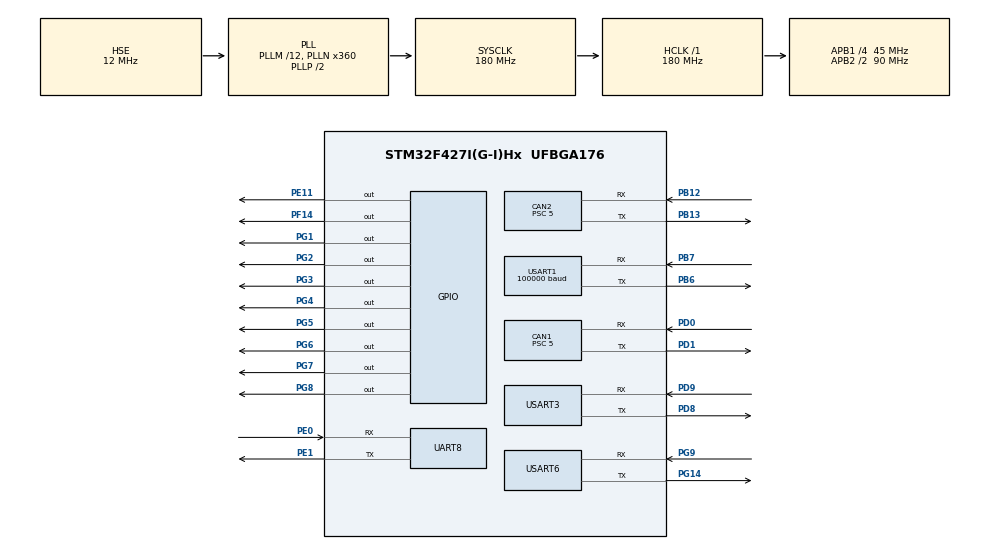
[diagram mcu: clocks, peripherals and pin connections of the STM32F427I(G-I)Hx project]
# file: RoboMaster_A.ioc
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CAN1.BS1=CAN_BS1_5TQ
CAN1.BS2=CAN_BS2_3TQ
CAN1.CalculateTimeQuantum=111.11111111111111
CAN1.Prescaler=5
CAN2.BS1=CAN_BS1_5TQ
CAN2.BS2=CAN_BS2_3TQ
CAN2.CalculateTimeQuantum=111.11111111111111
CAN2.Prescaler=5
Dma.Request0=USART1_RX
Dma.Request1=USART3_RX
Dma.Request2=USART6_RX
Dma.Request3=UART8_RX
Dma.UART8_RX.3.Direction=DMA_PERIPH_TO_MEMORY
Dma.UART8_RX.3.FIFOMode=DMA_FIFOMODE_DISABLE
Dma.UART8_RX.3.Instance=DMA1_Stream6
Dma.UART8_RX.3.MemDataAlignment=DMA_MDATAALIGN_BYTE
Dma.UART8_RX.3.MemInc=DMA_MINC_ENABLE
Dma.UART8_RX.3.Mode=DMA_CIRCULAR
Dma.UART8_RX.3.PeriphDataAlignment=DMA_PDATAALIGN_BYTE
Dma.UART8_RX.3.PeriphInc=DMA_PINC_DISABLE
Dma.UART8_RX.3.Priority=DMA_PRIORITY_LOW
Dma.USART1_RX.0.Direction=DMA_PERIPH_TO_MEMORY
Dma.USART1_RX.0.FIFOMode=DMA_FIFOMODE_DISABLE
Dma.USART1_RX.0.Instance=DMA2_Stream2
Dma.USART1_RX.0.MemDataAlignment=DMA_MDATAALIGN_BYTE
Dma.USART1_RX.0.MemInc=DMA_MINC_ENABLE
Dma.USART1_RX.0.Mode=DMA_CIRCULAR
Dma.USART1_RX.0.PeriphDataAlignment=DMA_PDATAALIGN_BYTE
Dma.USART1_RX.0.PeriphInc=DMA_PINC_DISABLE
Dma.USART1_RX.0.Priority=DMA_PRIORITY_LOW
Dma.USART3_RX.1.Direction=DMA_PERIPH_TO_MEMORY
Dma.USART3_RX.1.FIFOMode=DMA_FIFOMODE_DISABLE
Dma.USART3_RX.1.Instance=DMA1_Stream1
Dma.USART3_RX.1.MemDataAlignment=DMA_MDATAALIGN_BYTE
Dma.USART3_RX.1.MemInc=DMA_MINC_ENABLE
Dma.USART3_RX.1.Mode=DMA_NORMAL
Dma.USART3_RX.1.PeriphDataAlignment=DMA_PDATAALIGN_BYTE
Dma.USART3_RX.1.PeriphInc=DMA_PINC_DISABLE
Dma.USART3_RX.1.Priority=DMA_PRIORITY_LOW
Dma.USART6_RX.2.Direction=DMA_PERIPH_TO_MEMORY
Dma.USART6_RX.2.FIFOMode=DMA_FIFOMODE_DISABLE
Dma.USART6_RX.2.Instance=DMA2_Stream1
Dma.USART6_RX.2.MemDataAlignment=DMA_MDATAALIGN_BYTE
Dma.USART6_RX.2.MemInc=DMA_MINC_ENABLE
Dma.USART6_RX.2.Mode=DMA_NORMAL
Dma.USART6_RX.2.PeriphDataAlignment=DMA_PDATAALIGN_BYTE
Dma.USART6_RX.2.PeriphInc=DMA_PINC_DISABLE
Dma.USART6_RX.2.Priority=DMA_PRIORITY_LOW
FREERTOS.Tasks01=Default,0,128,DefaultTask,As weak,NULL,Dynamic,NULL,NULL;Chassis,0,128,ChassisTask,As weak,NULL,Dynamic,NULL,NULL;Gyroscope,3,128,GyroscopeTask,As weak,NULL,Dynamic,NULL,NULL;Control,3,128,ControlTask,As weak,NULL,Dynamic,NULL,NULL
Mcu.Family=STM32F4
Mcu.Name=STM32F427I(G-I)Hx
Mcu.Package=UFBGA176
NVIC.CAN1_RX0_IRQn=true\:0\:0\:false\:false\:true\:false\:true\:true
NVIC.CAN1_RX1_IRQn=true\:0\:0\:false\:false\:true\:false\:true\:true
NVIC.CAN1_TX_IRQn=true\:0\:0\:false\:false\:true\:false\:true\:true
NVIC.CAN2_RX0_IRQn=true\:0\:0\:false\:false\:true\:false\:true\:true
NVIC.CAN2_RX1_IRQn=true\:0\:0\:false\:false\:true\:false\:true\:true
NVIC.CAN2_TX_IRQn=true\:0\:0\:false\:false\:true\:false\:true\:true
NVIC.DMA1_Stream1_IRQn=true\:0\:0\:false\:false\:true\:false\:false\:true
NVIC.DMA1_Stream6_IRQn=true\:0\:0\:false\:false\:true\:true\:false\:true
NVIC.DMA2_Stream1_IRQn=true\:0\:0\:false\:false\:true\:true\:false\:true
NVIC.DMA2_Stream2_IRQn=true\:0\:0\:false\:false\:true\:false\:false\:true
NVIC.PriorityGroup=NVIC_PRIORITYGROUP_4
NVIC.TIM1_TRG_COM_TIM11_IRQn=true\:0\:0\:false\:false\:true\:false\:false\:true
NVIC.TIM8_BRK_TIM12_IRQn=true\:0\:0\:false\:false\:true\:false\:false\:true
NVIC.TimeBase=TIM8_BRK_TIM12_IRQn
NVIC.TimeBaseIP=TIM12
NVIC.UART8_IRQn=true\:0\:0\:false\:false\:true\:false\:true\:true
NVIC.USART1_IRQn=true\:0\:0\:false\:false\:true\:false\:true\:true
NVIC.USART3_IRQn=true\:0\:0\:false\:false\:true\:false\:true\:true
NVIC.USART6_IRQn=true\:0\:0\:false\:false\:true\:false\:true\:true
PB12.Mode=Slave
PB12.Signal=CAN2_RX
PB13.Mode=Slave
PB13.Signal=CAN2_TX
PB6.GPIO_PuPd=GPIO_PULLUP
PB6.Mode=Asynchronous
PB6.Signal=USART1_TX
PB7.GPIO_PuPd=GPIO_PULLUP
PB7.Mode=Asynchronous
PB7.Signal=USART1_RX
PD0.Mode=Master
PD0.Signal=CAN1_RX
PD1.Mode=Master
PD1.Signal=CAN1_TX
PD8.GPIO_PuPd=GPIO_PULLUP
PD8.Mode=Asynchronous
PD8.Signal=USART3_TX
PD9.GPIO_PuPd=GPIO_PULLUP
PD9.Mode=Asynchronous
PD9.Signal=USART3_RX
PE0.Mode=Asynchronous
PE0.Signal=UART8_RX
PE1.Mode=Asynchronous
PE1.Signal=UART8_TX
PE11.GPIO_PuPd=GPIO_PULLUP
PE11.GPIO_Speed=GPIO_SPEED_FREQ_VERY_HIGH
PE11.PinState=GPIO_PIN_SET
PE11.Signal=GPIO_Output
PE7.Signal=UART7_RX
PE8.Signal=UART7_TX
PF14.GPIO_PuPd=GPIO_PULLUP
PF14.GPIO_Speed=GPIO_SPEED_FREQ_VERY_HIGH
PF14.PinState=GPIO_PIN_SET
PF14.Signal=GPIO_Output
PG1.GPIO_PuPd=GPIO_PULLUP
PG1.GPIO_Speed=GPIO_SPEED_FREQ_VERY_HIGH
PG1.PinState=GPIO_PIN_SET
PG1.Signal=GPIO_Output
PG14.GPIO_PuPd=GPIO_PULLUP
PG14.Mode=Asynchronous
PG14.Signal=USART6_TX
PG2.GPIO_PuPd=GPIO_PULLUP
PG2.GPIO_Speed=GPIO_SPEED_FREQ_VERY_HIGH
PG2.PinState=GPIO_PIN_SET
PG2.Signal=GPIO_Output
PG3.GPIO_PuPd=GPIO_PULLUP
PG3.GPIO_Speed=GPIO_SPEED_FREQ_VERY_HIGH
PG3.PinState=GPIO_PIN_SET
PG3.Signal=GPIO_Output
PG4.GPIO_PuPd=GPIO_PULLUP
PG4.GPIO_Speed=GPIO_SPEED_FREQ_VERY_HIGH
PG4.PinState=GPIO_PIN_SET
PG4.Signal=GPIO_Output
PG5.GPIO_PuPd=GPIO_PULLUP
PG5.GPIO_Speed=GPIO_SPEED_FREQ_VERY_HIGH
PG5.PinState=GPIO_PIN_SET
PG5.Signal=GPIO_Output
PG6.GPIO_PuPd=GPIO_PULLUP
PG6.GPIO_Speed=GPIO_SPEED_FREQ_VERY_HIGH
PG6.PinState=GPIO_PIN_SET
PG6.Signal=GPIO_Output
PG7.GPIO_PuPd=GPIO_PULLUP
PG7.GPIO_Speed=GPIO_SPEED_FREQ_VERY_HIGH
PG7.PinState=GPIO_PIN_SET
PG7.Signal=GPIO_Output
PG8.GPIO_PuPd=GPIO_PULLUP
PG8.GPIO_Speed=GPIO_SPEED_FREQ_VERY_HIGH
PG8.PinState=GPIO_PIN_SET
PG8.Signal=GPIO_Output
PG9.GPIO_PuPd=GPIO_PULLUP
PG9.Mode=Asynchronous
PG9.Signal=USART6_RX
PH0/OSC_IN.Mode=HSE-External-Oscillator
PH0/OSC_IN.Signal=RCC_OSC_IN
PH1/OSC_OUT.Mode=HSE-External-Oscillator
PH1/OSC_OUT.Signal=RCC_OSC_OUT
ProjectManager.HeapSize=0x200
ProjectManager.StackSize=0x400
ProjectManager.TargetToolchain=MDK-ARM V5.27
RCC.48MHZClocksFreq_Value=90000000
RCC.AHBFreq_Value=180000000
RCC.APB1CLKDivider=RCC_HCLK_DIV4
RCC.APB1Freq_Value=45000000
RCC.APB1TimFreq_Value=90000000
RCC.APB2CLKDivider=RCC_HCLK_DIV2
RCC.APB2Freq_Value=90000000
RCC.APB2TimFreq_Value=180000000
RCC.CortexFreq_Value=180000000
RCC.HCLKFreq_Value=180000000
RCC.HSE_VALUE=12000000
RCC.HSI_VALUE=16000000
RCC.LSE_VALUE=32768
RCC.PLLM=12
RCC.PLLN=360
RCC.PLLSourceVirtual=RCC_PLLSOURCE_HSE
RCC.SYSCLKFreq_VALUE=180000000
RCC.SYSCLKSource=RCC_SYSCLKSOURCE_PLLCLK
RCC.VCOOutputFreq_Value=360000000
TIM1.Period=999
TIM1.Prescaler=8999
TIM2.Period=2499
TIM2.Prescaler=8999
TIM3.Period=9
TIM3.Prescaler=8999
UART8.VirtualMode=Asynchronous
USART1.BaudRate=100000
USART1.Parity=PARITY_EVEN
USART1.VirtualMode=VM_ASYNC
USART3.VirtualMode=VM_ASYNC
USART6.VirtualMode=VM_ASYNC
VP_FREERTOS_VS_CMSIS_V1.Mode=CMSIS_V1
VP_SYS_VS_tim12.Mode=TIM12
VP_TIM1_VS_ClockSourceINT.Mode=Internal
VP_TIM2_VS_ClockSourceINT.Mode=Internal
VP_TIM3_VS_ClockSourceINT.Mode=Internal
board=custom

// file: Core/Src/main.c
/* USER CODE BEGIN Header */
/**
  ******************************************************************************
  * @file           : main.c
  * @brief          : Main program body
  ******************************************************************************
  * @attention
  *
  * <h2><center>&copy; Copyright (c) 2020 STMicroelectronics.
  * All rights reserved.</center></h2>
  *
  * This software component is licensed by ST under BSD 3-Clause license,
  * the "License"; You may not use this file except in compliance with the
  * License. You may obtain a copy of the License at:
  *                        opensource.org/licenses/BSD-3-Clause
  *
  ******************************************************************************
  */
/* USER CODE END Header */
#include "main.h"
#include "cmsis_os.h"
#include "can.h"
#include "dma.h"
#include "tim.h"
#include "usart.h"
#include "gpio.h"

/* USER CODE BEGIN Includes */
#include "bsp_can.h"
#include "bsp_uart.h"
#include "packet.h"
#include "imu_data_decode.h"
#include "pid.h"
/* USER CODE END Includes */

void SystemClock_Config(void);
void MX_FREERTOS_Init(void);

int main(void)
{

  /* MCU Configuration--------------------------------------------------------*/

  /* Reset of all peripherals, Initializes the Flash interface and the Systick. */
  HAL_Init();

  /* Configure the system clock */
  SystemClock_Config();

  /* Initialize all configured peripherals */
  MX_GPIO_Init();
  MX_DMA_Init();
  MX_CAN1_Init();
  MX_CAN2_Init();
  MX_USART1_UART_Init();
  MX_UART8_Init();
  MX_USART3_UART_Init();
  MX_USART6_UART_Init();
  MX_TIM2_Init();
  MX_TIM3_Init();
  MX_TIM1_Init();
  /* USER CODE BEGIN 2 */
  can_user_init(&hcan1);
  can_user_init(&hcan2);
  dbus_uart_init();//遥控器DMA设置
  IMU_usart8_init();//陀螺仪DMA设置
  imu_data_decode_init();//陀螺仪数据解析
  pid_parameter_init(); //pid参数初始化
  /* USER CODE END 2 */

  /* Call init function for freertos objects (in freertos.c) */
  MX_FREERTOS_Init();
  /* Start scheduler */
  osKernelStart();

  /* We should never get here as control is now taken by the scheduler */
  /* Infinite loop */
  while (1)
  {

  }
}

void SystemClock_Config(void)
{
  RCC_OscInitTypeDef RCC_OscInitStruct = {0};
  RCC_ClkInitTypeDef RCC_ClkInitStruct = {0};

  /** Configure the main internal regulator output voltage
  */
  __HAL_RCC_PWR_CLK_ENABLE();
  __HAL_PWR_VOLTAGESCALING_CONFIG(PWR_REGULATOR_VOLTAGE_SCALE1);
  /** Initializes the RCC Oscillators according to the specified parameters
  * in the RCC_OscInitTypeDef structure.
  */
  RCC_OscInitStruct.OscillatorType = RCC_OSCILLATORTYPE_HSE;
  RCC_OscInitStruct.HSEState = RCC_HSE_ON;
  RCC_OscInitStruct.PLL.PLLState = RCC_PLL_ON;
  RCC_OscInitStruct.PLL.PLLSource = RCC_PLLSOURCE_HSE;
  RCC_OscInitStruct.PLL.PLLM = 12;
  RCC_OscInitStruct.PLL.PLLN = 360;
  RCC_OscInitStruct.PLL.PLLP = RCC_PLLP_DIV2;
  RCC_OscInitStruct.PLL.PLLQ = 4;
  if (HAL_RCC_OscConfig(&RCC_OscInitStruct) != HAL_OK)
  {
    Error_Handler();
  }
  /** Activate the Over-Drive mode
  */
  if (HAL_PWREx_EnableOverDrive() != HAL_OK)
  {
    Error_Handler();
  }
  /** Initializes the CPU, AHB and APB buses clocks
  */
  RCC_ClkInitStruct.ClockType = RCC_CLOCKTYPE_HCLK|RCC_CLOCKTYPE_SYSCLK
                              |RCC_CLOCKTYPE_PCLK1|RCC_CLOCKTYPE_PCLK2;
  RCC_ClkInitStruct.SYSCLKSource = RCC_SYSCLKSOURCE_PLLCLK;
  RCC_ClkInitStruct.AHBCLKDivider = RCC_SYSCLK_DIV1;
  RCC_ClkInitStruct.APB1CLKDivider = RCC_HCLK_DIV4;
  RCC_ClkInitStruct.APB2CLKDivider = RCC_HCLK_DIV2;

  if (HAL_RCC_ClockConfig(&RCC_ClkInitStruct, FLASH_LATENCY_5) != HAL_OK)
  {
    Error_Handler();
  }
}

void HAL_TIM_PeriodElapsedCallback(TIM_HandleTypeDef *htim)
{
  if (htim->Instance == TIM12) {
    HAL_IncTick();
  }
}

void Error_Handler(void)
{
}

/************************ (C) COPYRIGHT STMicroelectronics *****END OF FILE****/

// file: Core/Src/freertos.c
/* USER CODE BEGIN Header */
/**
  ******************************************************************************
  * File Name          : freertos.c
  * Description        : Code for freertos applications
  ******************************************************************************
  * @attention
  *
  * <h2><center>&copy; Copyright (c) 2020 STMicroelectronics.
  * All rights reserved.</center></h2>
  *
  * This software component is licensed by ST under Ultimate Liberty license
  * SLA0044, the "License"; You may not use this file except in compliance with
  * the License. You may obtain a copy of the License at:
  *                             www.st.com/SLA0044
  *
  ******************************************************************************
  */
/* USER CODE END Header */

#include "FreeRTOS.h"
#include "task.h"
#include "main.h"
#include "cmsis_os.h"

osThreadId DefaultHandle;
osThreadId ChassisHandle;
osThreadId GyroscopeHandle;
osThreadId ControlHandle;

void DefaultTask(void const * argument);
void ChassisTask(void const * argument);
void GyroscopeTask(void const * argument);
void ControlTask(void const * argument);

void MX_FREERTOS_Init(void); /* (MISRA C 2004 rule 8.1) */

/* GetIdleTaskMemory prototype (linked to static allocation support) */
void vApplicationGetIdleTaskMemory( StaticTask_t **ppxIdleTaskTCBBuffer, StackType_t **ppxIdleTaskStackBuffer, uint32_t *pulIdleTaskStackSize );

/* USER CODE BEGIN GET_IDLE_TASK_MEMORY */
static StaticTask_t xIdleTaskTCBBuffer;
static StackType_t xIdleStack[configMINIMAL_STACK_SIZE];

void vApplicationGetIdleTaskMemory( StaticTask_t **ppxIdleTaskTCBBuffer, StackType_t **ppxIdleTaskStackBuffer, uint32_t *pulIdleTaskStackSize )
{
  *ppxIdleTaskTCBBuffer = &xIdleTaskTCBBuffer;
  *ppxIdleTaskStackBuffer = &xIdleStack[0];
  *pulIdleTaskStackSize = configMINIMAL_STACK_SIZE;
  /* place for user code */
}
/* USER CODE END GET_IDLE_TASK_MEMORY */

void MX_FREERTOS_Init(void) {

  /* Create the thread(s) */
  /* definition and creation of Default */
  osThreadDef(Default, DefaultTask, osPriorityNormal, 0, 128);
  DefaultHandle = osThreadCreate(osThread(Default), NULL);

  /* definition and creation of Chassis */
  osThreadDef(Chassis, ChassisTask, osPriorityNormal, 0, 128);
  ChassisHandle = osThreadCreate(osThread(Chassis), NULL);

  /* definition and creation of Gyroscope */
  osThreadDef(Gyroscope, GyroscopeTask, osPriorityRealtime, 0, 128);
  GyroscopeHandle = osThreadCreate(osThread(Gyroscope), NULL);

  /* definition and creation of Control */
  osThreadDef(Control, ControlTask, osPriorityRealtime, 0, 128);
  ControlHandle = osThreadCreate(osThread(Control), NULL);

}

__weak void DefaultTask(void const * argument)
{
  for(;;)
  {
    osDelay(1);
  }
}

__weak void ChassisTask(void const * argument)
{
  for(;;)
  {
    osDelay(1);
  }
}

__weak void GyroscopeTask(void const * argument)
{
  for(;;)
  {
    osDelay(1);
  }
}

__weak void ControlTask(void const * argument)
{
  for(;;)
  {
    osDelay(1);
  }
}

/************************ (C) COPYRIGHT STMicroelectronics *****END OF FILE****/
